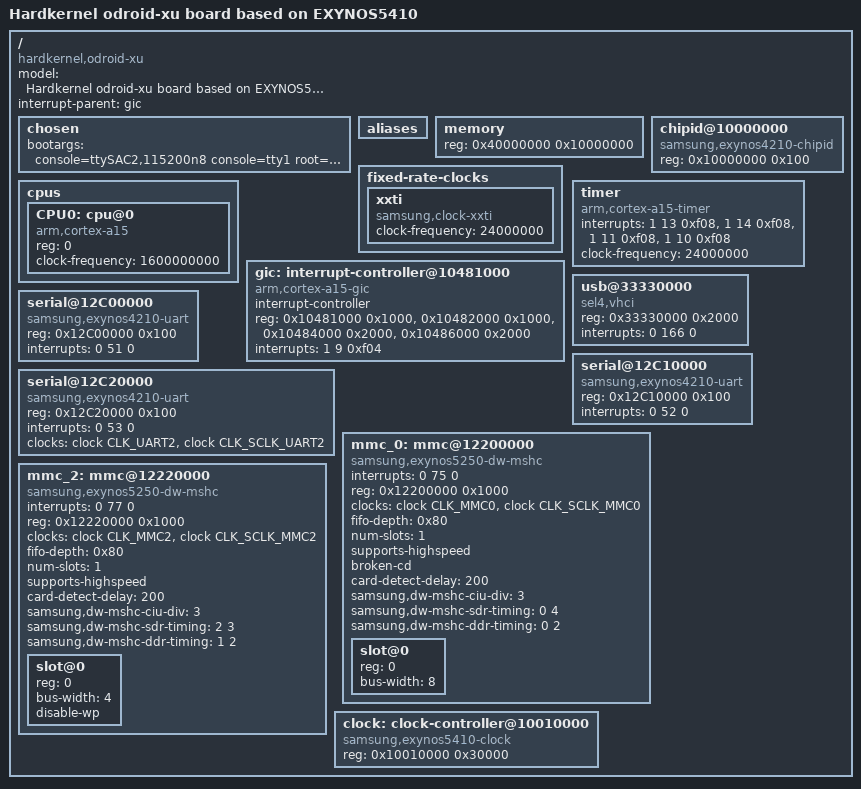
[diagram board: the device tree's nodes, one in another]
/*
 * Hardkernel odroid-xu board device tree source
 *
 * Copyright (c) 2013 Hardkernel Electronics Co., Ltd.
 *		http://www.hardkernel.com
 *
 * This program is free software; you can redistribute it and/or modify
 * it under the terms of the GNU General Public License version 2 as
 * published by the Free Software Foundation.
*/

/dts-v1/;
#include <dt-bindings/interrupt-controller/irq.h>
#include <dt-bindings/input/input.h>
#include <dt-bindings/gpio/gpio.h>
#include <dt-bindings/clock/exynos5410.h>
#include <dt-bindings/clk/exynos-audss-clk.h>

// Doesn't compile without this... ?
/ {};

/ {
	#address-cells = <1>;
	#size-cells = <1>;
	model = "Hardkernel odroid-xu board based on EXYNOS5410";
	compatible = "hardkernel,odroid-xu", "samsung,exynos5410";
	interrupt-parent = <&gic>;

	chosen {
		bootargs = "console=ttySAC2,115200n8 console=tty1 root=/dev/mmcblk0p2 rootwait rw debug loglevel=7 text";
	};

	aliases {
	};

	memory {
		device_type = "memory";
		reg = <0x40000000 0x10000000>;
	};

	chipid@10000000 {
		compatible = "samsung,exynos4210-chipid";
		reg = <0x10000000 0x100>;
	};

	fixed-rate-clocks {
		xxti {
			compatible = "samsung,clock-xxti";
			clock-frequency = <24000000>;
		};
	};

	cpus {
		#address-cells = <1>;
		#size-cells = <0>;

		CPU0: cpu@0 {
			device_type = "cpu";
			compatible = "arm,cortex-a15";
			reg = <0>;
			clock-frequency = <1600000000>;
		};
	};

	gic: interrupt-controller@10481000 {
		compatible = "arm,cortex-a15-gic", "arm,cortex-a9-gic";
		#interrupt-cells = <3>;
		interrupt-controller;
		reg =	<0x10481000 0x1000>,
			<0x10482000 0x1000>,
			<0x10484000 0x2000>,
			<0x10486000 0x2000>;
		interrupts = <1 9 0xf04>;
	};

	timer {
		compatible = "arm,cortex-a15-timer", "arm,armv7-timer";
		interrupts = <1 13 0xf08>,
			     <1 14 0xf08>,
			     <1 11 0xf08>,
			     <1 10 0xf08>;
		/* Unfortunately we need this since some versions of U-Boot
		 * on Exynos don't set the CNTFRQ register, so we need the
		 * value from DT.
		 */
		clock-frequency = <24000000>;
	};

	usb@33330000 {
		compatible = "sel4,vhci";
		reg = <0x33330000 0x2000>;
		interrupts = <0 166 0>;
	};

// These ports here just to be consistent with device ID
	serial@12C00000 {
		compatible = "samsung,exynos4210-uart";
		reg = <0x12C00000 0x100>;
		interrupts = <0 51 0>;
	};
	serial@12C10000 {
		compatible = "samsung,exynos4210-uart";
		reg = <0x12C10000 0x100>;
		interrupts = <0 52 0>;
	};
// Serial console 
	serial@12C20000 {
		compatible = "samsung,exynos4210-uart";
		reg = <0x12C20000 0x100>;
		interrupts = <0 53 0>;
		clocks = <&clock CLK_UART2>, <&clock CLK_SCLK_UART2>;
		clock-names = "uart", "clk_uart_baud0";
	};

	mmc_0: mmc@12200000 {
		compatible = "samsung,exynos5250-dw-mshc";
		interrupts = <0 75 0>;
		#address-cells = <1>;
		#size-cells = <0>;
		reg = <0x12200000 0x1000>;
		clocks = <&clock CLK_MMC0>, <&clock CLK_SCLK_MMC0>;
		clock-names = "biu", "ciu";
		fifo-depth = <0x80>;
		status = "okay";
		num-slots = <1>;
		supports-highspeed;
		broken-cd;
		card-detect-delay = <200>;
		samsung,dw-mshc-ciu-div = <3>;
		samsung,dw-mshc-sdr-timing = <0 4>;
		samsung,dw-mshc-ddr-timing = <0 2>;
		pinctrl-names = "default";
		slot@0 {
			reg = <0>;
			bus-width = <8>;
		};
	};

	mmc_2: mmc@12220000 {
		compatible = "samsung,exynos5250-dw-mshc";
		interrupts = <0 77 0>;
		#address-cells = <1>;
		#size-cells = <0>;
		reg = <0x12220000 0x1000>;
		clocks = <&clock CLK_MMC2>, <&clock CLK_SCLK_MMC2>;
		clock-names = "biu", "ciu";
		fifo-depth = <0x80>;
		status = "okay";
		num-slots = <1>;
		supports-highspeed;
		card-detect-delay = <200>;
		samsung,dw-mshc-ciu-div = <3>;
		samsung,dw-mshc-sdr-timing = <2 3>;
		samsung,dw-mshc-ddr-timing = <1 2>;
		pinctrl-names = "default";
		slot@0 {
			reg = <0>;
			bus-width = <4>;
			disable-wp;
		};
	};

	clock: clock-controller@10010000 {
		compatible = "samsung,exynos5410-clock";
		reg = <0x10010000 0x30000>;
		#clock-cells = <1>;
	};
};
